# MMCHS1 register map
Vendor: Texas Instruments
Peripheral module from a debugger description file (folder omap34xx).
Registers are 32-bit, access per field, reset 0x0 unless marked. A register's access mark holds for its fields unless they carry their own. Offsets are as the file gives them; lines under a group give offsets from that group; [hi:lo] are bit positions; {n}, {i} and the like mark numbered series; 'fields as' and 'values as' point back to an identical list; <NAME> marks a mode.

## MMCHS1 (part 1 of 2)
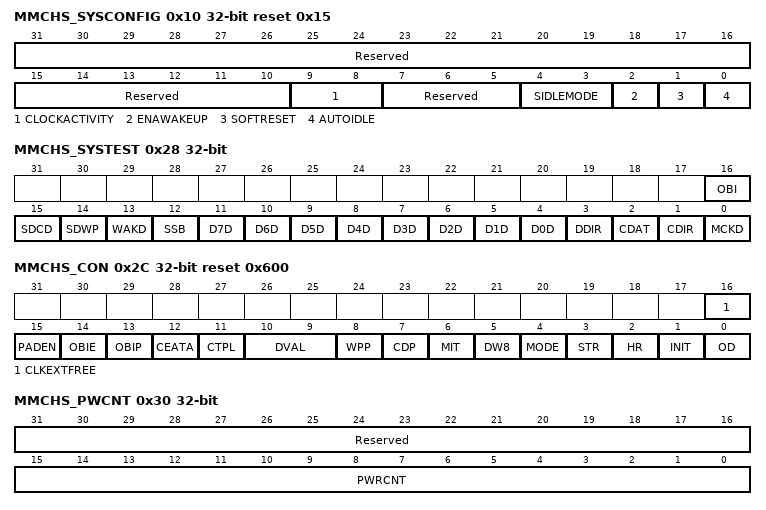
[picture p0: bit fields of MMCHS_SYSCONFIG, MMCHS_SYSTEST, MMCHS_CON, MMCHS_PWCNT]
0x10 MMCHS_SYSCONFIG reset 0x15 — System Configuration RegisterThis register allows controlling various parameters of the Interconnect interface.
  [31:10] Reserved ro — These bits are initialized to zero, and writes to them are ignored.
  [9:8] CLOCKACTIVITY rw — Clocks activity during wake up mode period.Bit8: Interface clockBit9: Functional clock
    0=Interface and Functional clock may be switched off; 1=Interface clock is maintained. Functional clock may be switched-off.; 2=Functional clock is maintained. Interface clock may be switched-off.; 3=Interface and Functional clocks are maintained
  [7:5] Reserved ro — These bits are initialized to zero, and writes to them are ignored.
  [4:3] SIDLEMODE rw — Power management
    0=If an idle request is detected, the MMC/SD/SDIO host controller acknowledges it unconditionally and goes in Inactive mode. Interrupt and DMA requests are unconditionally deasserted.; 1=If an idle request is detected, the request is ignored and the module keeps on behaving normally; 2=If an idle request is detected, the module will switch to wake up mode based on its internal activity, and the wake up capability can be used if the wake up capability is enabled (bit MMCi.[2] ENAWAKEUP bit is set to 1); 3=Reserved - do not use
  [2] ENAWAKEUP rw — Wake-up feature control
    0=Wake-up capability is disabled; 1=Wake-up capability is enabled
  [1] SOFTRESET rw — Software reset. The bit is automatically reset by the hardware. During reset, it always returns 0.
    0=SOFTRESET_0_r (Normal mode); 0=SOFTRESET_0_w (No effect.); 1=SOFTRESET_1_r (The module is reset.); 1=SOFTRESET_1_w (Trigger a module reset.)
  [0] AUTOIDLE rw — Internal Clock gating strategy
    0=Clocks are free-running; 1=Automatic clock gating strategy is applied, based on the interconnect and MMC interface activity
0x14 MMCHS_SYSSTATUS ro — System Status Register This register provides status information about the module excluding the interrupt status information
  [0] RESETDONE — Internal Reset Monitoring Note: the debounce clock , the interface clock and the functional clock shall be provided to the MMC/SD/SDIO host controller to allow the internal reset monitoring.
    0=RESETDONE_0_r (Internal module reset is on-going); 1=RESETDONE_1_r (Reset completed.)
0x24 MMCHS_CSRE rw — Card status response errorThis register enables the host controller to detect card status errors of response type R1, R1b for all cards and of R5, R5b and R6 response for cards types SD or SDIO. When a bit MMCi.[I] is set to 1, if the corresponding bit at the same position in the response MMCi.[I] is set to 1, the host controller indicates a card error (MMCi.[28] CERR bit) interrupt status to avoid the host driver reading the response register (MMCi.).Note: No automatic card error detection for autoCMD12 is implemented; the host system has to check autoCMD12 response register (MMCi.) for possible card errors.
  [31:0] CSRE — Card status response error
0x28 MMCHS_SYSTEST — System Test register This register is used to control the signals that connect to I/O pins when the module is configured in system test (SYSTEST) mode for boundary connectivity verification. Note: In SYSTEST mode, a write into MMCi. register will not start a transfer. The buffer behaves as a stack accessible only by the local host (push and pop operations). In this mode, the Transfer Block Size (MMCi.[10:0] BLEN bits) and the Blocks count for current transfer (MMCi.[31:16] NBLK bits) are needed to generate a Buffer write ready interrupt (MMCi.[4] BWR bit) or a Buffer read ready interrupt (MMCi.[5] BRR bit) and DMA requests if enabled.
  [16] OBI rw — Out-Of-Band Interrupt (OBI) data value.
    0=The Out-of-Band Interrupt pin is driven low; 1=The Out-of-Band Interrupt pin is driven high
  [15] SDCD ro — Card detect input signal (SDCD) data value
    0=The card detect pin is driven low; 1=The card detect pin is driven high
  [14] SDWP ro — Write protect input signal (SDWP) data value.
    0=The write protect pin SDWP is driven low; 1=The write protect pin SDWP is driven high
  [13] WAKD rw — Wake request output signal data value.
    0=WAKD_0_r (No action. Returns 0.); 0=WAKD_0_w (The pin SWAKEUP is driven low.); 1=WAKD_1_r (No action. Returns 1.); 1=WAKD_1_w (The pin SWAKEUP is driven high.)
  [12] SSB rw — Set status bit This bit must be cleared prior attempting to clear a status bit of the interrupt status register (MMCi.MMCHS_STAT).
    0=SSB_0_r (No action. Returns 0.); 0=SSB_0_w (Clear this SSB bit field. Writing 0 does not clear already set status bits.); 1=SSB_1_r (No action. Returns 1.); 1=SSB_1_w (Force to 1 all status bits of the interrupt status register (MMCi.) only if the corresponding bit field in the Interrupt signal enable register (MMCi.) is set.)
  [n+4] D{n}D rw (n=0..7) — DAT{n} input/output signal data value.
    0=D{n}D_0_r (If MMCi.[3] DDIR bit = 1 (input mode direction), returns the value on the DAT{n} line (low).If MMCi.[3] DDIR bit = 0 (output mode direction), returns 0.); 0=D{n}D_0_w (If MMCi.[3] DDIR bit = 0 (output mode direction), the DAT{n} line is driven low.If MMCi.[3] DDIR bit = 1 (input mode direction), no effect.); 1=D{n}D_1_r (If MMCi.[3] DDIR bit = 1 (input mode direction), returns the value on the DAT{n} line (high)If MMCi.[3] DDIR bit = 0 (output mode direction), returns 1.); 1=D{n}D_1_w (If MMCi.[3] DDIR bit = 0 (output mode direction), the DAT{n} line is driven high.If MMCi.[3] DDIR bit = 1 (input mode direction), no effect.)
  [3] DDIR rw — Control of the DAT[7:0] pins direction.
    0=DDIR_0_r (No action. Returns 0.); 0=DDIR_0_w (The DAT lines are outputs (host to card).); 1=DDIR_1_r (No action. Returns 1.); 1=DDIR_1_w (The DAT lines are inputs (card to host).)
  [2] CDAT rw — CMD input/output signal data value.
    0=CDAT_0_r (If MMCi.[1] CDIR bit = 1 (input mode direction), returns the value on the CMD line (low).If MMCi.[1] CDIR bit = 0 (output mode direction), returns 0 .); 0=CDAT_0_w (If MMCi.[1] CDIR bit = 0 (output mode direction), the CMD line is driven low.If MMCi.[1] CDIR bit = 1 (input mode direction), no effect.); 1=CDAT_1_r (If MMCi.[1] CDIR bit = 1 (input mode direction), returns the value on the CMD line (high)If MMCi.[1] CDIR bit = 0 (output mode direction), returns 1 .); 1=CDAT_1_w (If MMCi.[1] CDIR bit = 0 (output mode direction), the CMD line is driven high.If MMCi.[1] CDIR bit = 1 (input mode direction), no effect.)
  [1] CDIR rw — Control of the CMD pin direction.
    0=CDIR_0_r (No action. Returns 0.); 0=CDIR_0_w (The CMD line is an output (host to card).); 1=CDIR_1_r (No action. Returns 1.); 1=CDIR_1_w (The CMD line is an input (card to host) .)
  [0] MCKD rw — MMC clock output signal data value.
    0=MCKD_0_r (No action. Returns 0.); 0=MCKD_0_w (The output clock is driven low.); 1=MCKD_1_r (No action. Returns 1.); 1=MCKD_1_w (The output clock is driven high.)
0x2C MMCHS_CON reset 0x600 — Configuration register This register is used:- to select the functional mode for any card.- to send an initialization sequence to any card.- to enable the detection on the mmci_dat[1] signal of a card interrupt for SDIO cards only.And also to configure:- specific data and command transfers for MMC cards only.- the parameters related to the card detect and write protect input signals.
  [16] CLKEXTFREE rw — External clock free running. This register is used to maintain card clock out of transfer transaction to enable slave module (for example to generate a synchronous interrupt on mmci_dat[1]). The Clock will be maintain only if MMCi.MMCHS_SYSCTL[2] CEN bit is set.
    0=External card clock is cut off outside active transaction period; 1=External card clock is maintain even out of active transaction period only if MMCi.[2] CEN bit is set
  [15] PADEN rw — Control Power for MMC Lines. This register is only useful when MMC PADs contain power saving mechanism to minimize its leakage power. It works as a GPIO that directly control the ACTIVE pin of PADs. Excepted for mmci_dat[1], the signal is also combine outside the module with the dedicated power control MMCi.MMCHS_CON[11] CTPL bit.
    0=ADPIDLE module pin is not forced, it is automatically generated by the MMC fsms; 1=ADPIDLE module pin is forced to active state
  [14] OBIE rw — Out-of-Band Interrupt Enable (MMC cards only). This bit enables the detection of Out-of-Band Interrupt on MMCOBI input pin. The usage of the Out-of-Band signal (OBI) is optional and depends on the system integration.
    0=Out-of-Band interrupt detection disabled; 1=Out-of-Band interrupt detection enabled
  [13] OBIP rw — Out-of-Band Interrupt Polarity (MMC cards only). This bit selects the active level of the out-of-band interrupt coming from MMC cards. The usage of the Out-of-Band signal (OBI) is optional and depends on the system integration.
    0=active high level; 1=active low level
  [12] CEATA rw — CE-ATA control mode (MMC cards compliant with CE-ATA):By default, this bit is set to 0. It is use to indicate that next commands are considered as specific CE-ATA commands that potentially use 'command completion' features.
    0=Standard MMC/SD/SDIO mode; 1=CE-ATA mode.Next commands are considered as CE-ATA commands
  [11] CTPL rw — Control Power for mmci_dat[1] line (MMC and SD cards):By default, this bit is set to 0 and the host controller automatically disables all the input buffers outside of a transaction to minimize the leakage current. SDIO cards: When this bit is set to 1, the host controller automatically disables all the input buffers except the buffer of mmci_dat[1] outside of a transaction in order to detect asynchronous card interrupt on mmci_dat[1] line and minimize the leakage current of the buffers.
    0=Disable all the input buffers outside of a transaction; 1=Disable all the input buffers except the buffer of mmci_dat[1]outside of a transaction
  [10:9] DVAL rw — Debounce filter value (All cards) This register is used to define a debounce period to filter the card detect input signal (SDCD). The usage of the card detect input signal (SDCD) is optional and depends on the system integration and the type of the connector housing that accommodates the card.
    0=33 us debounce period; 1=231 us debounce period; 2=1 ms debounce period; 3=8.4 ms debounce period
  [8] WPP rw — Write protect polarity (SD and SDIO cards only) This bit selects the active level of the write protect input signal (SDWP). The usage of the write protect input signal (SDWP) is optional and depends on the system integration and the type of the connector housing that accommodates the card.
    0=Active high level; 1=Active low level
  [7] CDP rw — Card detect polarity (All cards) This bit selects the active level of the card detect input signal (SDCD). The usage of the card detect input signal (SDCD) is optional and depends on the system integration and the type of the connector housing that accommodates the card.
    0=Active high level; 1=Active low level
  [6] MIT rw — MMC interrupt command (Only for MMC cards.) This bit must be set to 1, when the next write access to the command register (MMCi.MMCHS_CMD) is for writing a MMC interrupt command (CMD40) requiring the command timeout detection to be disabled for the command response.
    0=Command timeout enabled; 1=Command timeout disabled
  [5] DW8 rw — 8-bit mode MMC select For SD/SDIO cards, this bit must be set to 0. For MMC card, this bit must be set following a valid SWITCH command (CMD6) with the correct value and extend CSD index written in the argument. Prior to this command, the MMC card configuration register (CSD and EXT_CSD) must be verified for compliancy with MMC standard specification.
    0=1-bit or 4-bit Data width (mmci_dat[0] or mmci_dat[3:0] used, MMC, SD cards); 1=8-bit Data width (mmci_dat[7:0] used, MMC cards)
  [4] MODE rw — Mode select (All cards) These bits select the functional mode.
    0=Functional mode.Transfers to the MMC/SD/SDIO cards follow the card protocol. MMC clock is enabled. MMC/SD transfers are operated under the control of the MMCi. register.; 1=SYSTEST mode
  [3] STR rw — Stream command (Only for MMC cards). This bit must be set to 1 only for the stream data transfers (read or write) of the adtc commands. Stream read is a class 1 command (CMD11: READ_DAT_UNTIL_STOP). Stream write is a class 3 command (CMD20: WRITE_DAT_UNTIL_STOP).
    0=Block oriented data transfer; 1=Stream oriented data transfer
  [2] HR rw — Broadcast host response (Only for MMC cards).This register is used to force the host to generate a 48-bit response for bc command type.It can be used to terminate the interrupt mode by generating a CMD40 response by the core. In order to have the host response to be generated in open drain mode, the register MMCHS_CON[OD] must be set to 1.When MMCi.MMCHS_CON[12] CEATA bit is set to 1 and MMCi.MMCHS_ARG set to 0x00000000, when writing 0x00000000 into MMCi.MMCHS_CMD register, the host controller performs a 'command completion signal disable' token (i.e. mmci_cmd line held to '0' during 47 cycles followed by a 1).
    0=The host does not generate a 48-bit response instead of a command; 1=The host generates a 48-bit response instead of a command or a command completion signal disable token
  [1] INIT rw — Send initialization stream (All cards). When this bit is set to 1, and the card is idle, an initialization sequence is sent to the card. An initialization sequence consists of setting the mmci_cmd line to 1 during 80 clock cycles. The initialization sequence is mandatory - but it is not required to do it through this bit - this bit makes it easier. Clock divider (MMCi.MMCHS_SYSCTL[15:6] CLKD bits) should be set to ensure that 80 clock periods are greater than 1ms. Note: in this mode, there is no command sent to the card and no response is expected. A command complete interrupt will be generated once the initialization sequence is completed. MMCi.MMCHS_STAT[0] CC bit can be polled.
    0=The host does not send an initialization sequence; 1=The host sends an initialization sequence
  [0] OD rw — Card open drain mode (Only for MMC cards). This bit must be set to 1 for MMC card commands 1, 2, 3 and 40, and if the MMC card bus is operating in open-drain mode during the response phase to the command sent. Typically, during card identification mode when the card is either in idle, ready or ident state.It is also necessary to set this bit to 1, for a broadcast host response (see Broadcast host response register MMCi.MMCHS_CON[2] HR bit)
    0=No Open Drain; 1=Open Drain or Broadcast host response
0x30 MMCHS_PWCNT — Power counter register This register is used to program a mmc counter to delay command transfers after activating the PAD power, this value depends on PAD characteristics and voltage.
  [31:16] Reserved ro — These bits are initialized to zero, and writes to them are ignored. Reads return 0.
  [15:0] PWRCNT rw — Power counter register.This register is used to introduce a delay between the PAD ACTIVE pin assertion and the command issued.
    0=No additional delay added; 1=TCF delay (card clock period); 2=TCF x 2 delay (card clock period); 0xFFFE=TCF x 65534 delay (card clock period); 0xFFFF=TCF x 65535 delay (card clock period)
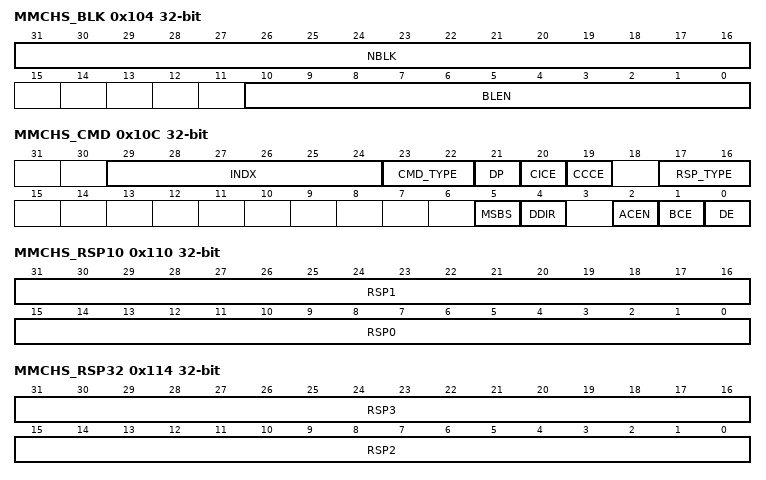
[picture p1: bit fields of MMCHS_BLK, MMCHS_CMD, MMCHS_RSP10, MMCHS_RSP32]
0x104 MMCHS_BLK — Transfer Length Configuration registerThis register shall be used for any card.
  [31:16] NBLK rw — Blocks count for current transfer.This register is enabled when Block count Enable (MMCi.MMCHS_CMD[1] BCE bit) is set to 1 and is valid only for multiple block transfers. Setting the block count to 0 results no data blocks being transferred. Note: The host controller decrements the block count after each block transfer and stops when the count reaches zero. This register can be accessed only if no transaction is executing (i.e., after a transaction has stopped). Read operations during transfers may return an invalid value and write operation will be ignored. In suspend context, the number of blocks yet to be transferred can be determined by reading this register. When restoring transfer context prior to issuing a Resume command, The local host shall restore the previously saved block count.
    0=Stop count; 1=1 block; 2=2 blocks; 0xFFFF=65535 blocks
  [10:0] BLEN rw — Transfer Block Size. This register specifies the block size for block data transfers. Read operations during transfers may return an invalid value, and write operations are ignored. When a CMD12 command is issued to stop the transfer, a read of the BLEN field after transfer completion (MMCi.MMCHS_STAT[1] TC bit set to 1) will not return the true byte number of data length while the stop occurs but the value written in this register before transfer is launched.
    0=No data transfer; 1=1 byte block length; 2=2 bytes block length; 3=3 bytes block length; 0x1FF=511 bytes block length; 0x200=512 bytes block length; 0x3FF=1023 bytes block length; 0x400=1024 bytes block length
0x108 MMCHS_ARG rw — Command argument Register This register contains command argument specified as bit 39-8 of Command-Format These registers must be initialized prior to sending the command itself to the card (write action into the register MMCi. register). Only exception is for a command index specifying stuff bits in arguments, making a write unnecessary.
  [31:0] ARG — Command argument bits [31:0]
0x10C MMCHS_CMD — Command and transfer mode registerMMCi.[31:16] = the command registerMMCi.[15:0] = the transfer mode. This register configures the data and command transfers. A write into the most significant byte send the command. A write into MMCi.[15:0] registers during data transfer has no effect. This register shall be used for any card.
  [29:24] INDX rw — Command index Binary encoded value from 0 to 63 specifying the command number send to card
    0=CMD0 or ACMD0; 1=CMD1 or ACMD1; 63=CMD63 or ACMD63
  [23:22] CMD_TYPE rw — Command type. This register specifies three types of special command: Suspend, Resume and Abort. These bits shall be set to 0b00 for all other commands.
    0=Others Commands; 1=Upon CMD52 'Bus Suspend' operation; 2=Upon CMD52 'Function Select' operation; 3=Upon CMD12 or CMD52 'I/O Abort' command
  [21] DP rw — Data present select. This register indicates that data is present and mmci_dat line shall be used. It must be set to 0 in the following conditions:- Command using only mmci_cmd line-Command with no data transfer but using busy signal on mmci_dat[0]-Resume command
    0=Command with no data transfer; 1=Command with data transfer
  [20] CICE rw — Command Index check enable. This bit must be set to 1 to enable index check on command response to compare the index field in the response against the index of the command. If the index is not the same in the response as in the command, it is reported as a command index error (MMCi.MMCHS_STAT[19] CIE bit set to1) Note: The CICE bit cannot be configured for an Auto CMD12, then index check is automatically checked when this command is issued.
    0=Index check disable; 1=Index check enable
  [19] CCCE rw — Command CRC check enable. This bit must be set to 1 to enable CRC7 check on command response to protect the response against transmission errors on the bus. If an error is detected, it is reported as a command CRC error (MMCi.MMCHS_STAT[17] CCRC bit set to 1). Note: The CCCE bit cannot be configured for an Auto CMD12, and then CRC check is automatically checked when this command is issued.
    0=CRC7 check disable; 1=CRC7 check enable
  [17:16] RSP_TYPE rw — Response type. This bits defines the response type of the command.
    0=No response; 1=Response Length 136 bits; 2=Response Length 48 bits; 3=Response Length 48 bits with busy after response
  [5] MSBS rw — Multi/Single block select. This bit must be set to 1 for data transfer in case of multi block command. For any others command this bit shall be set to 0.
    0=Single block. If this bit is 0, it is not necessary to set the register MMCi.[31:16] NBLK bits.; 1=Multi block. When Block Count is disabled (MMCi.[1] BCE bit is set to 0) in Multiple block transfers (MMCi.[5] MSBS bit is set to 1), the module can perform infinite transfer.
  [4] DDIR rw — Data transfer Direction. Select This bit defines either data transfer will be a read or a write.
    0=Data Write (host to card); 1=Data Read (card to host)
  [2] ACEN rw — Auto CMD12 Enable. (SD cards only). When this bit is set to 1, the host controller issues a CMD12 automatically after the transfer completion of the last block. The Host Driver shall not set this bit to issue commands that do not require CMD12 to stop data transfer.For CE-ATA commands (MMCi.MMCHS_CON[12] CEATA bit set to 1), auto CMD12 is useless; therefore when this bit is set the mechanism to detect command completion signal, named CCS, interrupt is activated.
    0=Auto CMD12 disable; 1=Auto CMD12 enable or CCS detection enabled
  [1] BCE rw — Block Count Enable (Multiple block transfers only). This bit is used to enable the block count register (MMCHS_BLK[31:16] NBLK bits). When Block Count is disabled (MMCHS_CMD[1] BCE bit is set to 0) in Multiple block transfers (MMCHS_CMD[5] MSBS bits is set to 1), the module can perform infinite transfer.
    0=Block count disabled for infinite transfer; 1=Block count enabled for multiple block transfer with known number of blocks
  [0] DE rw — DMA Enable. This bit is used to enable DMA mode for host data access.
    0=DMA mode disable; 1=DMA mode enable
0x110 MMCHS_RSP10 ro — Command response[31:0] Register This 32-bit register holds bits positions [31:0] of command response type R1/R1b/R2/R3/R4/R5/R5b/R6
  [31:16] RSP1 — R1/R1b (normal response) /R3/R4/R5/R5b/R6 : Command Response [39:24]R2: Command Response [31:16]
  [15:0] RSP0 — R1/R1b (normal response) /R3/R4/R5/R5b/R6 : Command Response [23:8]R2: Command Response [15:0]
0x114 MMCHS_RSP32 ro — Command response[63:32] Register This 32-bit register holds bits positions [63:32] of command response type R2
  [31:16] RSP3 — R2: Command Response [63:48]
  [15:0] RSP2 — R2: Command Response [47:32]
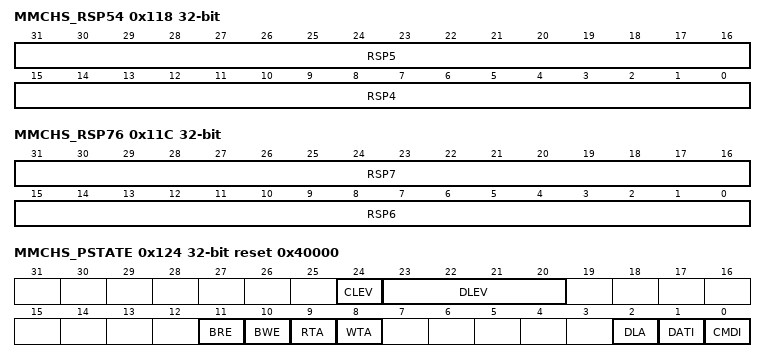
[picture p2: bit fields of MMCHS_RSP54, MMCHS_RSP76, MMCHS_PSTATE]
0x118 MMCHS_RSP54 ro — Command response[95:64] Register This 32-bit register holds bits positions [95:64] of command response type R2
  [31:16] RSP5 — R2: Command Response [95:80]
  [15:0] RSP4 — R2: Command Response [79:64]
0x11C MMCHS_RSP76 ro — Command response[127:96] RegisterThis 32-bit register holds bits positions [127:96] of command response type R2
  [31:16] RSP7 — R1b (Auto CMD12 response): Command Response [39:24]R2: Command Response [127:112]
  [15:0] RSP6 — R1b (Auto CMD12 response): Command Response [23:8]R2: Command Response [111:96]
0x120 MMCHS_DATA rw — Data Register This register is the 32-bit entry point of the buffer for read or write data transfers. The buffer size is 32bits x256(1024 bytes). Bytes within a word are stored and read in little endian format. This buffer can be used as two 512 byte buffers to transfer data efficiently without reducing the throughput. Sequential and contiguous access is necessary to increment the pointer correctly. Random or skipped access is not allowed. In little endian, if the local host accesses this register byte-wise or 16bit-wise, the least significant byte (bits [7:0]) must always be written/read first. The update of the buffer address is done on the most significant byte write for full 32-bit DATA register or on the most significant byte of the last word of block transfer. Example 1: Byte or 16-bit access Mbyteen[3:0]=0001 (1-byte) => Mbyteen[3:0]=0010 (1-byte) => Mbyteen[3:0]=1100 (2-bytes) OK Mbyteen[3:0]=0001 (1-byte) => Mbyteen[3:0]=0010 (1-byte) => Mbyteen[3:0]=0100 (1-byte) OK Mbyteen[3:0]=0001 (1-byte) => Mbyteen[3:0]=0010 (1-byte) => Mbyteen[3:0]=1000 (1-byte) Bad
  [31:0] DATA — Data Register [31:0] In functional mode (MMCI.MMCHS_CON[4] MODE bit set to the default value 0): A read access to this register is allowed only when the buffer read enable status is set to 1 (MMCi.MMCHS_PSTATE[11] BRE bit), otherwise a bad access (MMCi.MMCHS_STAT[29] BADA bit) is signaled. A write access to this register is allowed only when the buffer write enable status is set to 1 (MMCi.MMCHS_PSTATE[10] BWE bit), otherwise a bad access (MMCi.MMCHS_STAT[29] BADA bit) is signaled and the data is not written.
0x124 MMCHS_PSTATE ro reset 0x40000 (reset mask 0xFE0FFFFF) — Present state register. The Host can get status of the Host Controller from this 32-bit read only register.
  [24] CLEV — mmci_cmd line signal level.This status is used to check the mmci_cmd line level to recover from errors, and for debugging.The value of this register after reset depends on the mmci_cmd line level at that time.
    0=CLEV_0_r (The mmci_cmd line level is 0.); 1=CLEV_1_r (The mmci_cmd line level is 1.)
  [23:20] DLEV — mmci_dat[3:0] line signal levelmmci_dat[3] =&gt; bit 23mmci_dat[2] =&gt; bit 22mmci_dat[1] =&gt; bit 21mmci_dat[0] =&gt; bit 20This status is used to check mmci_dat line level to recover from errors, and for debugging. This is especially useful in detecting the busy signal level from mmci_dat[0].The value of these registers after reset depends on the mmci_dat lines level at that time.
  [11] BRE — Buffer read enable.This bit is used for non-DMA read transfers. It indicates that a complete block specified by MMCi.MMCHS_BLK[10:0] BLEN bits has been written in the buffer and is ready to be read.It is set to 0 when the entire block is read from the buffer. It is set to 1 when a block data is ready in the buffer and generates the Buffer read ready status of interrupt (MMCi.MMCHS_STAT[5] BRR bit).
    0=BRE_0_r (Read BLEN bytes disable); 1=BRE_1_r (Read BLEN bytes enable. Readable data exists in the buffer.)
  [10] BWE — Buffer Write enable.This status is used for non-DMA write transfers. It indicates if space is available for write data.
    0=BWE_0_r (There is no room left in the buffer to write BLEN bytes of data.); 1=BWE_1_r (There is enough space in the buffer to write BLEN bytes of data.)
  [9] RTA — Read transfer active.This status is used for detecting completion of a read transfer. It is set to 1 after the end bit of read command or by activating a continue request (MMCi.MMCHS_HCTL[17] CR bit) following a stop at block gap request. This bit is set to 0 when all data have been read by the local host after last block or after a stop at block gap request.
    0=RTA_0_r (No valid data on the mmci_dat lines.); 1=RTA_1_r (Read data transfer on going.)
  [8] WTA — Write transfer active.This status indicates a write transfer active. It is set to 1 after the end bit of write command or by activating a continue request (MMCi.MMCHS_HCTL[17] CR bit) following a stop at block gap request. This bit is set to 0 when CRC status has been received after last block or after a stop at block gap request.
    0=WTA_0_r (No valid data on the mmci_dat lines.); 1=WTA_1_r (Write data transfer on going.)
  [2] DLA — mmci_dat line active.This status bit indicates whether one of the mmci_dat line is in use. In the case of read transactions (card to host):This bit is set to 1 after the end bit of read command or by activating continue request MMCi.MMCHS_HCTL[17] CR bit. This bit is set to 0 when the host controller received the end bit of the last data block or at the beginning of the read wait mode. In the case of write transactions (host to card):This bit is set to 1 after the end bit of write command or by activating continue request MMCi.MMCHS_HCTL[17] CR bit.This bit is set to 0 on the end of busy event for the last block; host controller must wait 8 clock cycles with line not busy to really consider not 'busy state' or after the busy block as a result of a stop at gap request.
    0=DLA_0_r (mmci_dat Line inactive); 1=DLA_1_r (mmci_dat Line active)
  [1] DATI — Command inhibit (mmci_dat).This status bit is generated if either mmci_dat line is active (MMCi.MMCHS_PSTATE[2] DLA bit) or Read transfer is active (MMCi.MMCHS_PSTATE[9] RTA bit) or when a command with busy is issued. This bit prevents the local host to issue a command.A change of this bit from 1 to 0 generates a transfer complete interrupt (MMCi.MMCHS_STAT[1] TC bit).
    0=DATI_0_r (Issuing of command using the mmci_dat lines is allowed); 1=DATI_1_r (Issuing of command using mmci_dat lines is not allowed)
  [0] CMDI — Command inhibit(mmci_cmd).This status bit indicates that the mmci_cmd line is in use.This bit is set to 0 when the most significant byte is written into the command register. This bit is not set when Auto CMD12 is transmitted. This bit is set to 0 in either the following cases: - After the end bit of the command response, excepted if there is a command conflict error (MMCi.MMCHS_STAT[17] CCRC bit or MMCi.MMCHS_STAT[18] CEB bit set to 1) or a Auto CMD12 is not executed (MMCi.MMCHS_AC12[0] ACNE bit). - After the end bit of the command without response (MMCi.MMCHS_CMD[17:16] RSP_TYPE bits set to '00'). In case of a command data error is detected (MMCi.MMCHS_STAT[19] CTO bit set to 1), this register is not automatically cleared.
    0=CMDI_0_r (Issuing of command using mmci_cmd line is allowed); 1=CMDI_1_r (Issuing of command using mmci_cmd line is not allowed)
